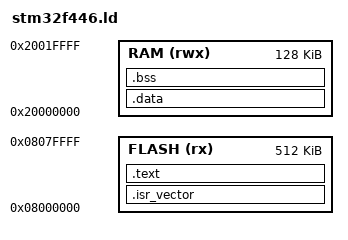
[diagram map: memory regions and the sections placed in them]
/* STM32F446RE: 512K flash @ 0x08000000, 128K contiguous SRAM @ 0x20000000
 * (112K SRAM1 + 16K SRAM2 are contiguous on this part, so they are declared
 * as one region -- the frame buffer needs ~38K in one piece). */
MEMORY
{
  FLASH (rx)  : ORIGIN = 0x08000000, LENGTH = 512K
  RAM   (rwx) : ORIGIN = 0x20000000, LENGTH = 128K
}

_estack = ORIGIN(RAM) + LENGTH(RAM);

SECTIONS
{
  .isr_vector : { KEEP(*(.isr_vector)) } > FLASH

  .text :
  {
    *(.text*)
    *(.rodata*)
    . = ALIGN(4);
    _etext = .;
  } > FLASH

  .data : AT (_etext)
  {
    . = ALIGN(4);
    _sdata = .;
    *(.data*)
    . = ALIGN(4);
    _edata = .;
  } > RAM

  .bss :
  {
    . = ALIGN(4);
    _sbss = .;
    *(.bss*)
    *(COMMON)
    . = ALIGN(4);
    _ebss = .;
  } > RAM

  /DISCARD/ : { *(.ARM.exidx*) *(.ARM.attributes) }
}
